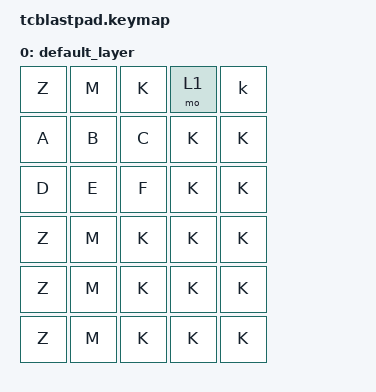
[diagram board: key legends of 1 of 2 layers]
/ {
    keymap {
        compatible = "zmk,keymap";

        default_layer { // Layer 0
            // -------------------------------------
            // |     Z     |     M     |     K     |
            // |     A     |     B     |     C     |
            // |     D     |     E     |     F     |
            bindings = <
                &kp Z    &kp M    &kp K     &mo 1   &kp k
                &kp A    &kp B    &kp C     &kp K   &kp K
                &kp D    &kp E    &kp F     &kp K   &kp K
                &kp Z    &kp M    &kp K     &kp K   &kp K
                &kp Z    &kp M    &kp K     &kp K   &kp K
                &kp Z    &kp M    &kp K     &kp K   &kp K
            >;
        };

        bt_layer {
                bindings = <
                    &none       &none       &bootloader     &none   &none
                    &none       &none       &bt BT_CLR  &none &none
                    &bt BT_SEL 0  &bt BT_SEL 1      &bt BT_SEL 2
                    &none &none &none &none &none
                    &none &none &none &none &none
                    &none &none &none &none &none
                >;
        }
    };
 };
